VERSION ""

NS_ :

BS_:

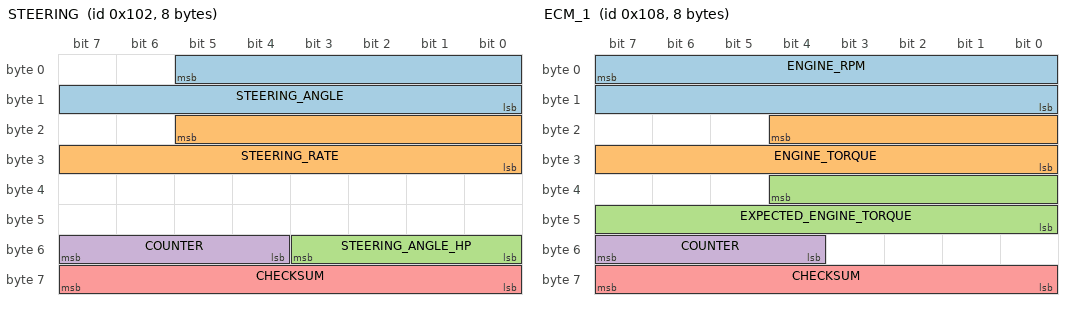
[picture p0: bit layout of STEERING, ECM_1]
BO_ 258 STEERING: 8 XXX
 SG_ STEERING_ANGLE : 5|14@0+ (0.5,-2048) [-2048|2047] "deg" XXX
 SG_ STEERING_RATE : 21|14@0+ (0.5,-2048) [-2048|2047] "deg/s" XXX
 SG_ STEERING_ANGLE_HP : 48|4@1+ (0.1,-0.4) [-0.4|0.4] "deg" XXX
 SG_ COUNTER : 55|4@0+ (1,0) [0|15] "" XXX
 SG_ CHECKSUM : 63|8@0+ (1,0) [0|255] "" XXX

BO_ 264 ECM_1: 8 XXX
 SG_ ENGINE_RPM : 7|16@0+ (1,0) [0|65535] "" XXX
 SG_ ENGINE_TORQUE : 20|13@0+ (0.25,-500) [-500|1547.5] "Nm" XXX
 SG_ EXPECTED_ENGINE_TORQUE : 36|13@0+ (0.25,-500) [-500|1547.5] "Nm" XXX
 SG_ COUNTER : 55|4@0+ (1,0) [0|15] "" XXX
 SG_ CHECKSUM : 63|8@0+ (1,0) [0|255] "" XXX

BO_ 280 ECM_TRQ: 8 XXX
 SG_ ENGINE_TORQ_MAX : 4|13@0+ (.25,-500) [-500|1547.5] "NM" XXX
 SG_ ENGINE_TORQ_MIN : 20|13@0+ (.25,-500) [-500|1547.5] "NM" XXX

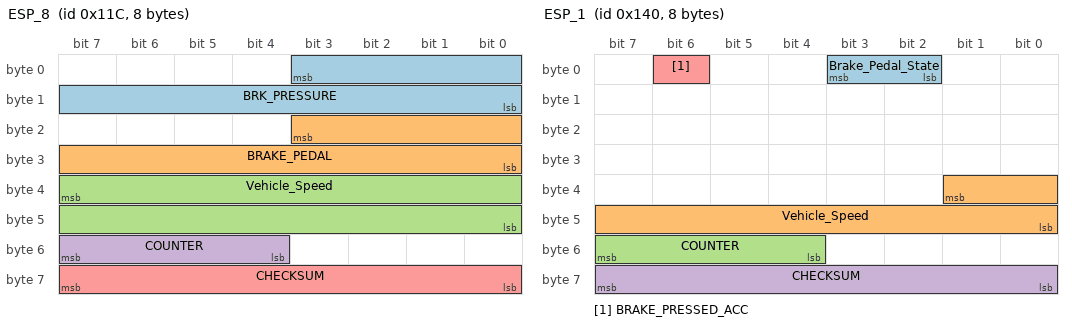
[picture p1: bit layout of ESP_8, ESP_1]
BO_ 284 ESP_8: 8 XXX
 SG_ BRK_PRESSURE : 3|12@0+ (1,0) [0|1] "" XXX
 SG_ BRAKE_PEDAL : 19|12@0+ (1,0) [0|1] "" XXX
 SG_ Vehicle_Speed : 39|16@0+ (0.0078125,0) [0|511.984375] "km/h" XXX
 SG_ COUNTER : 55|4@0+ (1,0) [0|15] "" XXX
 SG_ CHECKSUM : 63|8@0+ (1,0) [0|255] "" XXX

BO_ 320 ESP_1: 8 XXX
 SG_ Brake_Pedal_State : 2|2@1+ (1,0) [0|0] "" XXX
 SG_ Vehicle_Speed : 33|10@0+ (0.5,0) [0|511] "km/h" XXX
 SG_ COUNTER : 55|4@0+ (1,0) [0|15] "" XXX
 SG_ CHECKSUM : 63|8@0+ (1,0) [0|255] "" XXX
 SG_ BRAKE_PRESSED_ACC : 6|1@0+ (1,0) [0|3] "" XXX

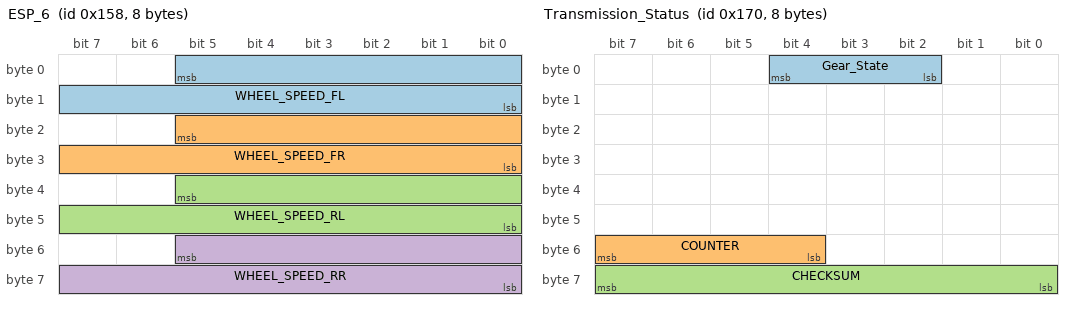
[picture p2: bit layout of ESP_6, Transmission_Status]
BO_ 344 ESP_6: 8 XXX
 SG_ WHEEL_SPEED_FL : 5|14@0+ (0.5,0) [0|8191] "rpm" XXX
 SG_ WHEEL_SPEED_FR : 21|14@0+ (0.5,0) [0|8191] "rpm" XXX
 SG_ WHEEL_SPEED_RL : 37|14@0+ (0.5,0) [0|8191] "rpm" XXX
 SG_ WHEEL_SPEED_RR : 53|14@0+ (0.5,0) [0|8191] "rpm" XXX

BO_ 368 Transmission_Status: 8 XXX
 SG_ Gear_State : 2|3@1+ (1,0) [0|15] "" XXX
 SG_ COUNTER : 55|4@0+ (1,0) [0|15] "" XXX
 SG_ CHECKSUM : 63|8@0+ (1,0) [0|255] "" XXX

BO_ 464 ORC_1: 8 XXX
 SG_ SEATBELT_DRIVER_UNLATCHED : 13|1@0+ (1,0) [0|1] "" XXX

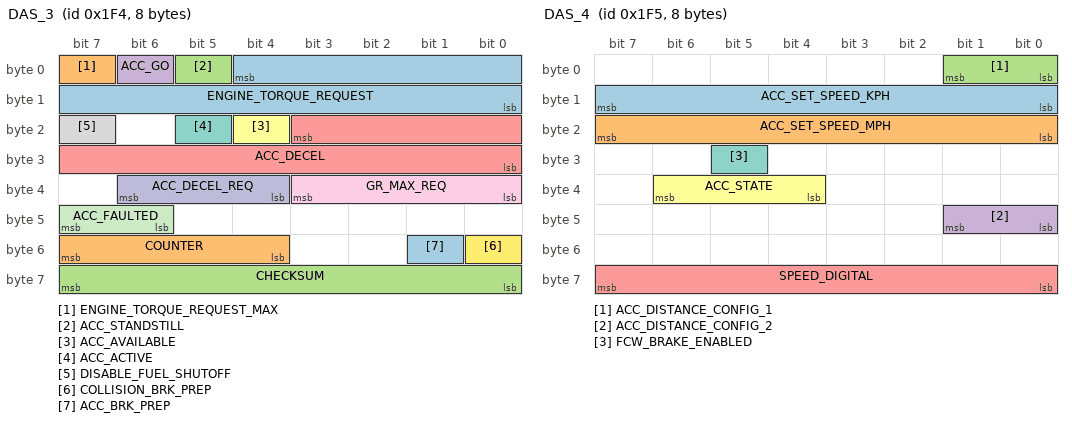
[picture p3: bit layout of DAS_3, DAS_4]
BO_ 500 DAS_3: 8 XXX
 SG_ ENGINE_TORQUE_REQUEST : 4|13@0+ (0.25,-500) [-500|1547.5] "Nm" XXX
 SG_ ENGINE_TORQUE_REQUEST_MAX : 7|1@0+ (1,0) [0|1] "" XXX
 SG_ ACC_STANDSTILL : 5|1@0+ (1,0) [0|1] ""  XXX
 SG_ ACC_GO : 6|1@1+ (1,0) [0|0] "" XXX
 SG_ ACC_DECEL : 19|12@0+ (0.004885,-16) [-16|4] "m/s2" XXX
 SG_ ACC_AVAILABLE : 20|1@0+ (1,0) [0|1] "" XXX
 SG_ ACC_ACTIVE : 21|1@0+ (1,0) [0|1] "" XXX
 SG_ DISABLE_FUEL_SHUTOFF : 23|1@1+ (1,0) [0|0] "" XXX
 SG_ GR_MAX_REQ : 32|4@1+ (1,0) [0|0] "" XXX
 SG_ ACC_DECEL_REQ : 36|3@1+ (1,0) [0|0] "" XXX
 SG_ ACC_FAULTED : 46|2@1+ (1,0) [0|0] "" XXX
 SG_ COLLISION_BRK_PREP : 48|1@1+ (1,0) [0|0] "" XXX
 SG_ ACC_BRK_PREP : 49|1@1+ (1,0) [0|0] "" XXX
 SG_ COUNTER : 55|4@0+ (1,0) [0|15] "" XXX
 SG_ CHECKSUM : 63|8@0+ (1,0) [0|255] "" XXX

BO_ 501 DAS_4: 8 XXX
 SG_ ACC_SET_SPEED_KPH : 15|8@0+ (1,0) [0|3] "km/h" XXX
 SG_ ACC_SET_SPEED_MPH : 23|8@0+ (1,0) [0|3] "mph" XXX
 SG_ ACC_DISTANCE_CONFIG_1 : 1|2@0+ (1,0) [0|3] "" XXX
 SG_ ACC_DISTANCE_CONFIG_2 : 41|2@0+ (1,0) [0|3] "" XXX
 SG_ SPEED_DIGITAL : 63|8@0+ (1,0) [0|255] "mph" XXX
 SG_ ACC_STATE : 38|3@0+ (1,0) [0|7] "" XXX
 SG_ FCW_BRAKE_ENABLED : 29|1@0+ (1,0) [0|1] "" XXX

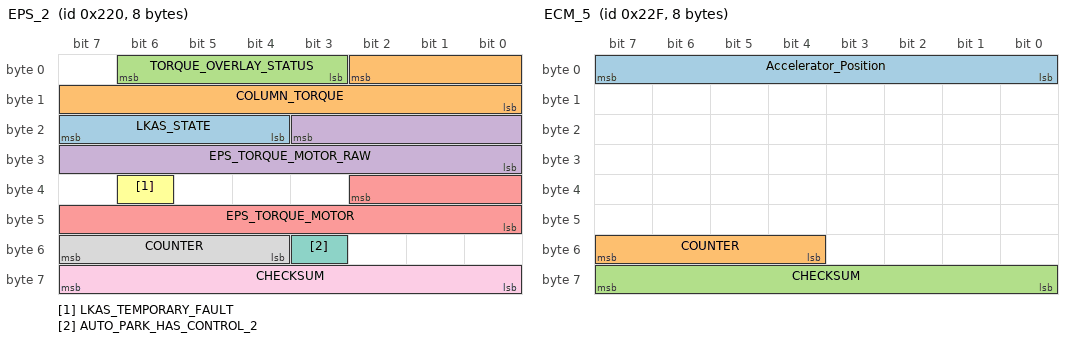
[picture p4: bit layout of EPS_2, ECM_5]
BO_ 544 EPS_2: 8 XXX
 SG_ LKAS_STATE : 23|4@0+ (1,0) [0|15] "" XXX
 SG_ COLUMN_TORQUE : 2|11@0+ (1,-1024) [-1024|1023] "" XXX
 SG_ TORQUE_OVERLAY_STATUS : 6|4@0+ (1,0) [0|15] "" XXX
 SG_ EPS_TORQUE_MOTOR_RAW : 19|12@0+ (1,-2048) [-2048|2047] "" XXX
 SG_ EPS_TORQUE_MOTOR : 34|11@0+ (1,-1024) [-1024|1023] "" XXX
 SG_ LKAS_TEMPORARY_FAULT : 38|1@0+ (1,0) [0|1] "" XXX
 SG_ AUTO_PARK_HAS_CONTROL_2 : 51|1@0+ (1,0) [0|1] "" XXX
 SG_ COUNTER : 55|4@0+ (1,0) [0|15] "" XXX
 SG_ CHECKSUM : 63|8@0+ (1,0) [0|255] "" XXX

BO_ 559 ECM_5: 8 XXX
 SG_ Accelerator_Position : 0|8@1+ (0.4,0) [0|100] "%" XXX
 SG_ COUNTER : 55|4@0+ (1,0) [0|15] "" XXX
 SG_ CHECKSUM : 63|8@0+ (1,0) [0|255] "" XXX

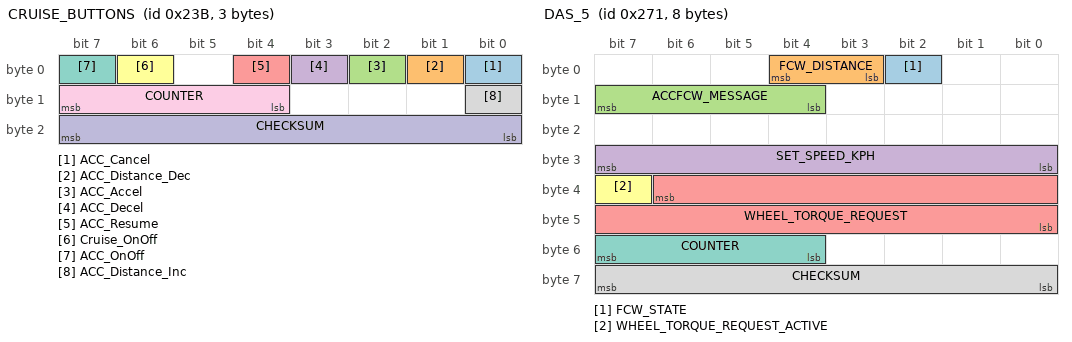
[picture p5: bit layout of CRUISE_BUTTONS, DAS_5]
BO_ 571 CRUISE_BUTTONS: 3 XXX
 SG_ ACC_Cancel : 0|1@1+ (1,0) [0|0] "" XXX
 SG_ ACC_Distance_Dec : 1|1@1+ (1,0) [0|0] "" XXX
 SG_ ACC_Accel : 2|1@1+ (1,0) [0|0] "" XXX
 SG_ ACC_Decel : 3|1@1+ (1,0) [0|0] "" XXX
 SG_ ACC_Resume : 4|1@0+ (1,0) [0|1] "" XXX
 SG_ Cruise_OnOff : 6|1@1+ (1,0) [0|0] "" XXX
 SG_ ACC_OnOff : 7|1@1+ (1,0) [0|0] "" XXX
 SG_ ACC_Distance_Inc : 8|1@1+ (1,0) [0|0] "" XXX
 SG_ COUNTER : 15|4@0+ (1,0) [0|15] "" XXX
 SG_ CHECKSUM : 23|8@0+ (1,0) [0|255] "" XXX

BO_ 625 DAS_5: 8 XXX
 SG_ FCW_STATE : 2|1@1+ (1,0) [0|0] ""  XXX
 SG_ FCW_DISTANCE : 3|2@1+ (1,0) [0|0] ""  XXX
 SG_ ACCFCW_MESSAGE : 12|4@1+ (1,0) [0|0] ""  XXX
 SG_ SET_SPEED_KPH : 24|8@1+ (1,0) [0|250] "km/h"  XXX
 SG_ WHEEL_TORQUE_REQUEST : 38|15@0+ (1,-7767) [-7767|24999] "Nm"  XXX
 SG_ WHEEL_TORQUE_REQUEST_ACTIVE : 39|1@1+ (1,0) [0|0] ""  XXX
 SG_ COUNTER : 55|4@0+ (1,0) [0|15] "" XXX
 SG_ CHECKSUM : 63|8@0+ (1,0) [0|255] "" XXX

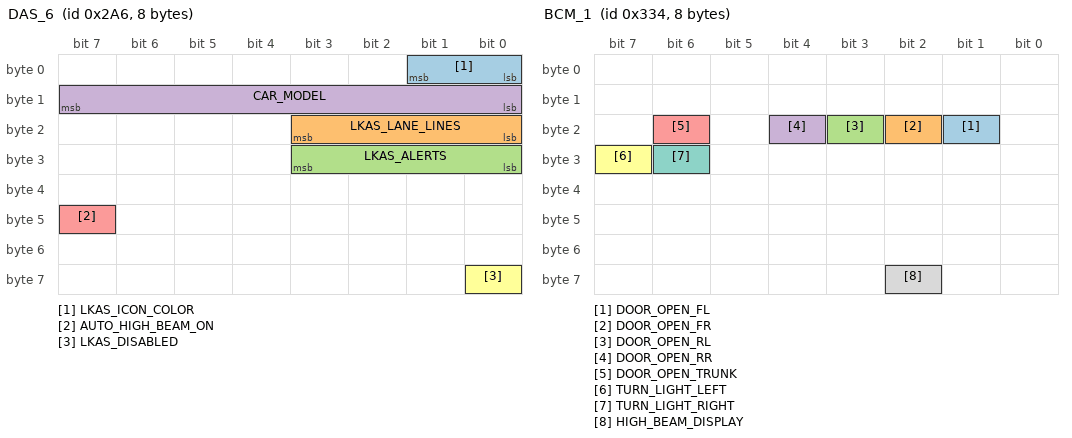
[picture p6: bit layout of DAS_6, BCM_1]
BO_ 678 DAS_6: 8 XXX
 SG_ LKAS_ICON_COLOR : 1|2@0+ (1,0) [0|3] "" XXX
 SG_ LKAS_LANE_LINES : 19|4@0+ (1,0) [0|1] "" XXX
 SG_ LKAS_ALERTS : 27|4@0+ (1,0) [0|1] "" XXX
 SG_ CAR_MODEL : 15|8@0+ (1,0) [0|255] "" XXX
 SG_ AUTO_HIGH_BEAM_ON : 47|1@1+ (1,0) [0|0] "" XXX
 SG_ LKAS_DISABLED : 56|1@1+ (1,0) [0|0] "" XXX

BO_ 720 BSM_1: 6 XXX
 SG_ RIGHT_STATUS : 5|1@0+ (1,0) [0|1] "" XXX
 SG_ LEFT_STATUS : 2|1@0+ (1,0) [0|1] "" XXX

BO_ 792 STEERING_LEVERS: 8 XXX
 SG_ TURN_SIGNALS : 0|2@1+ (1,0) [0|3] "" XXX
 SG_ HIGH_BEAM_PRESSED : 2|1@0+ (1,0) [0|3] "" XXX

BO_ 820 BCM_1: 8 XXX
 SG_ DOOR_OPEN_FL : 17|1@0+ (1,0) [0|1] "" XXX
 SG_ DOOR_OPEN_FR : 18|1@0+ (1,0) [0|1] "" XXX
 SG_ DOOR_OPEN_RL : 19|1@0+ (1,0) [0|1] "" XXX
 SG_ DOOR_OPEN_RR : 20|1@0+ (1,0) [0|1] "" XXX
 SG_ DOOR_OPEN_TRUNK : 22|1@0+ (1,0) [0|1] "" XXX
 SG_ TURN_LIGHT_LEFT : 31|1@0+ (1,0) [0|1] "" XXX
 SG_ TURN_LIGHT_RIGHT : 30|1@0+ (1,0) [0|1] "" XXX
 SG_ HIGH_BEAM_DISPLAY : 58|1@0+ (1,0) [0|1] "" XXX

BO_ 514 SPEED_1: 8 XXX
 SG_ SPEED_LEFT : 7|12@0+ (0.071028,0) [0|65535] "m/s" XXX
 SG_ SPEED_RIGHT : 23|12@0+ (0.071028,0) [0|1023] "m/s" XXX

BO_ 653 BRAKE_MODULE: 2 XXX
 SG_ BRAKE_PRESSURE : 15|8@0+ (1,0) [0|255] "" XXX
 SG_ BRAKE_PRESSED : 4|1@0+ (1,0) [0|4] "" XXX

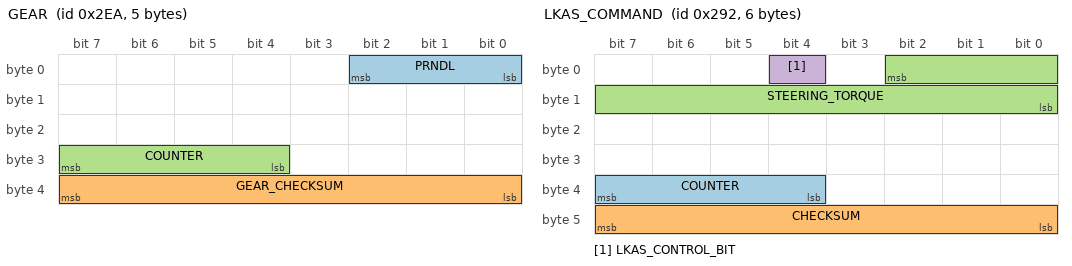
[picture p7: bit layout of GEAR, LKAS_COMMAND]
BO_ 746 GEAR: 5 XXX
 SG_ PRNDL : 2|3@0+ (1,0) [0|7] "" XXX
 SG_ GEAR_CHECKSUM : 39|8@0+ (1,0) [0|255] "" XXX
 SG_ COUNTER : 31|4@0+ (1,0) [0|15] "" XXX

BO_ 736 TRIP: 8 XXX
 SG_ COUNTER : 7|16@0+ (1,0) [0|65535] "Meters" XXX
 SG_ COUNTER_2 : 23|16@0+ (1,0) [0|65535] "Meters" XXX

BO_ 658 LKAS_COMMAND: 6 XXX
 SG_ COUNTER : 39|4@0+ (1,0) [0|15] "" XXX
 SG_ CHECKSUM : 47|8@0+ (1,0) [0|255] "" XXX
 SG_ STEERING_TORQUE : 2|11@0+ (1,-1024) [0|1] "" XXX
 SG_ LKAS_CONTROL_BIT : 4|1@0+ (1,0) [0|1] "" XXX

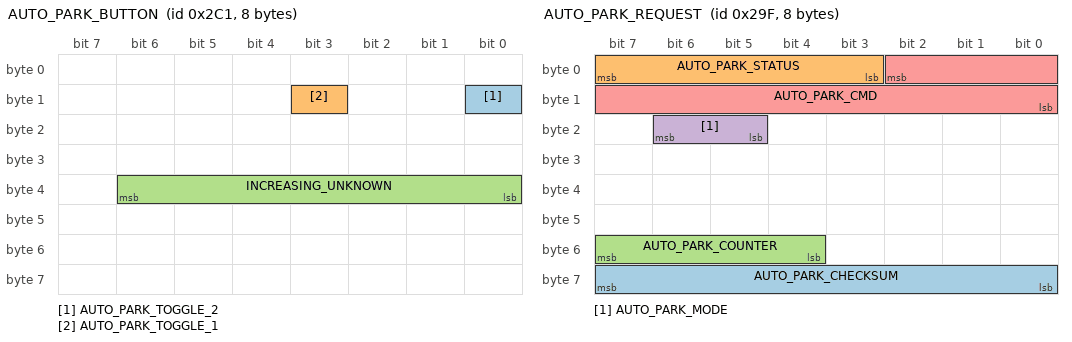
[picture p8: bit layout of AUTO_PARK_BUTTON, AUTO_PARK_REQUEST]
BO_ 705 AUTO_PARK_BUTTON: 8 XXX
 SG_ AUTO_PARK_TOGGLE_2 : 8|1@0+ (1,0) [0|1] "" XXX
 SG_ AUTO_PARK_TOGGLE_1 : 11|1@0+ (1,0) [0|1] "" XXX
 SG_ INCREASING_UNKNOWN : 38|7@0+ (1,0) [0|15] "" XXX

BO_ 719 AUTO_PARK_SIGNALS_1: 8 XXX
 SG_ AUTO_PARK_UNKNOWN_1 : 7|16@0+ (1,0) [0|31] "" XXX

BO_ 671 AUTO_PARK_REQUEST: 8 XXX
 SG_ AUTO_PARK_CHECKSUM : 63|8@0+ (1,0) [0|255] "" XXX
 SG_ AUTO_PARK_STATUS : 7|5@0+ (1,0) [0|15] "" XXX
 SG_ AUTO_PARK_COUNTER : 55|4@0+ (1,0) [0|15] "" XXX
 SG_ AUTO_PARK_MODE : 22|2@0+ (1,0) [0|3] "" XXX
 SG_ AUTO_PARK_CMD : 2|11@0+ (1,-1024) [0|1] "NM" XXX

BO_ 784 AUTO_PARK_LESS_INTERESTING: 8 XXX
 SG_ INCREASING_UNKNOWN : 55|8@0+ (1,0) [0|7] "" XXX
 SG_ AUTO_PARK_PERPENDICULAR_2 : 61|1@0+ (1,0) [0|255] "" XXX

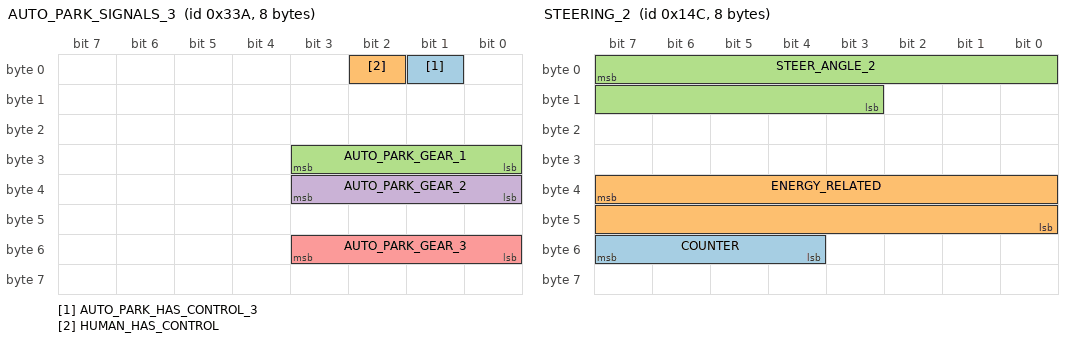
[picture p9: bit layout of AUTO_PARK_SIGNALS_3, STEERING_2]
BO_ 826 AUTO_PARK_SIGNALS_3: 8 XXX
 SG_ AUTO_PARK_HAS_CONTROL_3 : 1|1@0+ (1,0) [0|1] "" XXX
 SG_ HUMAN_HAS_CONTROL : 2|1@0+ (1,0) [0|1] "" XXX
 SG_ AUTO_PARK_GEAR_1 : 27|4@0+ (1,0) [0|255] "" XXX
 SG_ AUTO_PARK_GEAR_2 : 35|4@0+ (1,0) [0|15] "" XXX
 SG_ AUTO_PARK_GEAR_3 : 51|4@0+ (1,0) [0|15] "" XXX

BO_ 332 STEERING_2: 8 XXX
 SG_ COUNTER : 55|4@0+ (1,0) [0|15] "" XXX
 SG_ ENERGY_RELATED : 39|16@0+ (1,0) [0|65535] "" XXX
 SG_ STEER_ANGLE_2 : 7|13@0+ (0.3187251,-1307.888) [-360|360] "deg" XXX

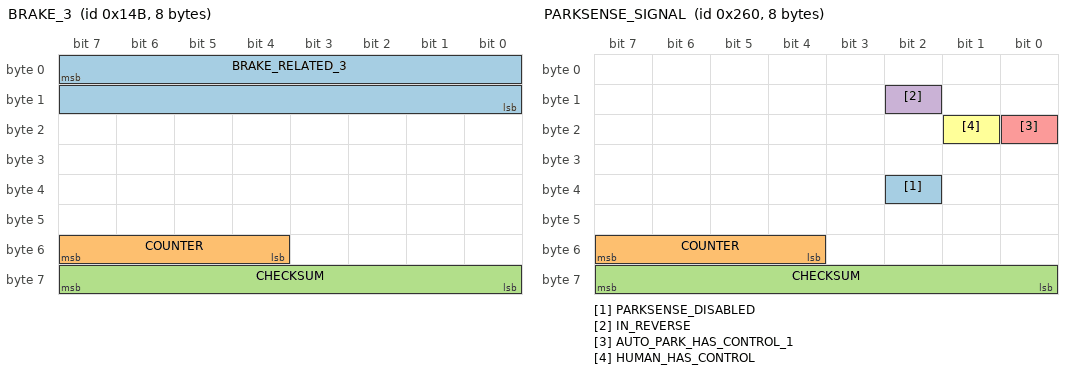
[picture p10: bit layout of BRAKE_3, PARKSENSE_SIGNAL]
BO_ 331 BRAKE_3: 8 XXX
 SG_ BRAKE_RELATED_3 : 7|16@0+ (1,0) [0|65535] "" XXX
 SG_ COUNTER : 55|4@0+ (1,0) [0|15] "" XXX
 SG_ CHECKSUM : 63|8@0+ (1,0) [0|255] "" XXX

BO_ 608 PARKSENSE_SIGNAL: 8 XXX
 SG_ PARKSENSE_DISABLED : 34|1@0+ (1,0) [0|1] "" XXX
 SG_ COUNTER : 55|4@0+ (1,0) [0|15] "" XXX
 SG_ CHECKSUM : 63|8@0+ (1,0) [0|255] "" XXX
 SG_ IN_REVERSE : 10|1@0+ (1,0) [0|255] "" XXX
 SG_ AUTO_PARK_HAS_CONTROL_1 : 16|1@0+ (1,0) [0|255] "" XXX
 SG_ HUMAN_HAS_CONTROL : 17|1@0+ (1,0) [0|3] "" XXX

BO_ 729 LKAS_HEARTBIT: 5 XXX
 SG_ LKAS_STATUS_OK : 31|16@0+ (1,0) [0|65535] "" XXX

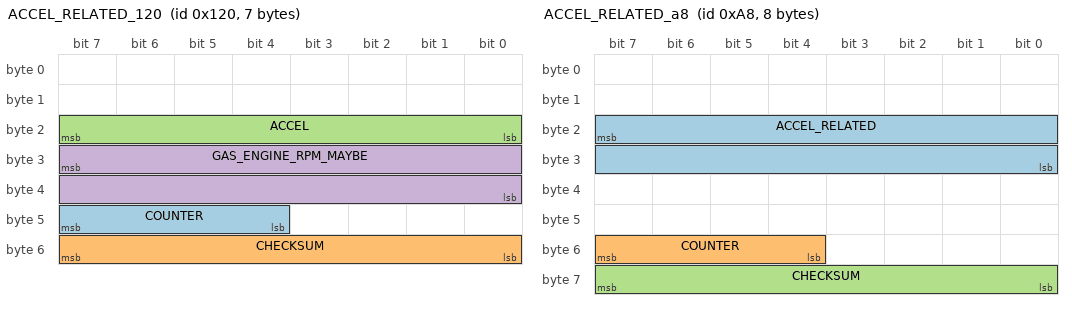
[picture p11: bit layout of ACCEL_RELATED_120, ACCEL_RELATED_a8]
BO_ 288 ACCEL_RELATED_120: 7 XXX
 SG_ COUNTER : 47|4@0+ (1,0) [0|15] "" XXX
 SG_ CHECKSUM : 55|8@0+ (1,0) [0|255] "" XXX
 SG_ ACCEL : 23|8@0+ (1,0) [0|255] "" XXX
 SG_ GAS_ENGINE_RPM_MAYBE : 31|16@0+ (1,0) [0|65535] "" XXX

BO_ 257 ACCEL_RELATED_101: 5 XXX
 SG_ ENERGY_OR_RPM : 31|8@0+ (1,0) [0|255] "" XXX

BO_ 825 AUDIBLE_BEEP_339: 2 XXX
 SG_ BEEP_339 : 7|16@0+ (1,0) [0|65535] "" XXX

BO_ 168 ACCEL_RELATED_a8: 8 XXX
 SG_ ACCEL_RELATED : 23|16@0+ (1,0) [0|65535] "" XXX
 SG_ COUNTER : 55|4@0+ (1,0) [0|15] "" XXX
 SG_ CHECKSUM : 63|8@0+ (1,0) [0|255] "" XXX

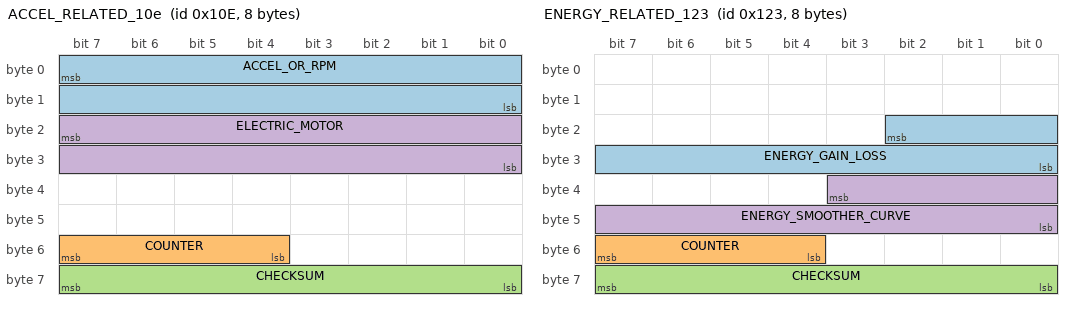
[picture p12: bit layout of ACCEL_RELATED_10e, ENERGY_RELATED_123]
BO_ 270 ACCEL_RELATED_10e: 8 XXX
 SG_ ACCEL_OR_RPM : 7|16@0+ (1,0) [0|255] "" XXX
 SG_ COUNTER : 55|4@0+ (1,0) [0|15] "" XXX
 SG_ CHECKSUM : 63|8@0+ (1,0) [0|255] "" XXX
 SG_ ELECTRIC_MOTOR : 23|16@0+ (1,0) [0|65535] "" XXX

BO_ 291 ENERGY_RELATED_123: 8 XXX
 SG_ ENERGY_GAIN_LOSS : 18|11@0- (1,0) [0|255] "" XXX
 SG_ COUNTER : 55|4@0+ (1,0) [0|15] "" XXX
 SG_ CHECKSUM : 63|8@0+ (1,0) [0|255] "" XXX
 SG_ ENERGY_SMOOTHER_CURVE : 35|12@0+ (1,0) [0|2047] "" XXX

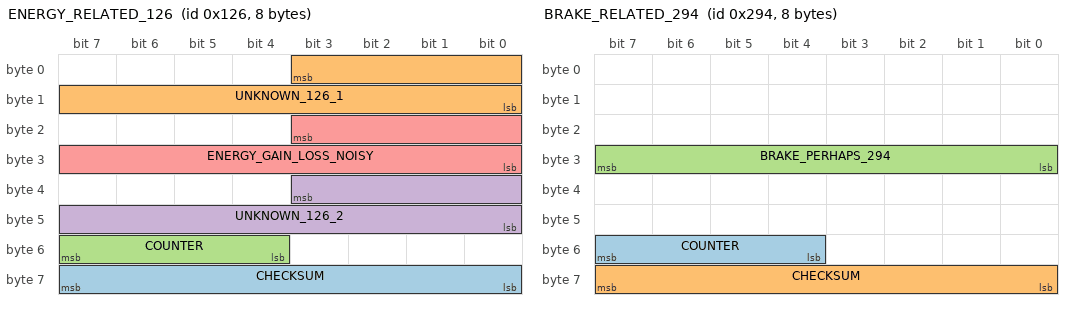
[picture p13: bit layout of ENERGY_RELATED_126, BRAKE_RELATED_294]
BO_ 294 ENERGY_RELATED_126: 8 XXX
 SG_ CHECKSUM : 63|8@0+ (1,0) [0|255] "" XXX
 SG_ UNKNOWN_126_1 : 3|12@0+ (1,0) [0|4095] "" XXX
 SG_ COUNTER : 55|4@0+ (1,0) [0|15] "" XXX
 SG_ UNKNOWN_126_2 : 35|12@0+ (1,0) [0|4095] "" XXX
 SG_ ENERGY_GAIN_LOSS_NOISY : 19|12@0+ (1,0) [0|2047] "" XXX

BO_ 308 ACCEL_GAS_134: 8 XXX
 SG_ COUNTER : 55|4@0+ (1,0) [0|15] "" XXX
 SG_ ACCEL_134 : 46|7@0+ (1,0) [0|127] "" XXX

BO_ 532 ENERGY_RELATED_214: 8 XXX
 SG_ NOISY_SLOWLY_DECREASING : 16|9@0+ (1,0) [0|255] "" XXX
 SG_ ENERGY_RELATED : 0|9@0+ (1,0) [0|255] "" XXX

BO_ 655 CHARGING_MAYBE_28F: 8 XXX
 SG_ CHARGING : 1|2@0+ (1,0) [0|3] "" XXX

BO_ 660 BRAKE_RELATED_294: 8 XXX
 SG_ COUNTER : 55|4@0+ (1,0) [0|15] "" XXX
 SG_ CHECKSUM : 63|8@0+ (1,0) [0|255] "" XXX
 SG_ BRAKE_PERHAPS_294 : 31|8@0+ (1,0) [0|255] "" XXX

BO_ 764 ACCEL_RELATED_2FC: 8 XXX
 SG_ ACCEL_2FC : 13|6@0+ (1,0) [0|255] "" XXX

BO_ 816 TRACTION_BUTTON: 8 XXX
 SG_ TRACTION_OFF : 19|1@0+ (1,0) [0|3] "" XXX
 SG_ TOGGLE_PARKSENSE : 52|1@0+ (1,0) [0|3] "" XXX

BO_ 878 ACCEL_RELATED_36E: 8 XXX
 SG_ ACCEL_OR_RPM_2 : 15|8@0+ (1,0) [0|255] "" XXX
 SG_ ACCEL_OR_RPM_1 : 7|8@0+ (1,0) [0|255] "" XXX

BO_ 324 SPEED_2: 8 XXX
 SG_ SPEED_2 : 31|16@0+ (0.01,0) [0|255] "m/s" XXX

BO_ 832 UNKNOWN_340: 8 XXX
 SG_ SPEED_DIGITAL : 63|8@0+ (1,0) [0|255] "mph" XXX

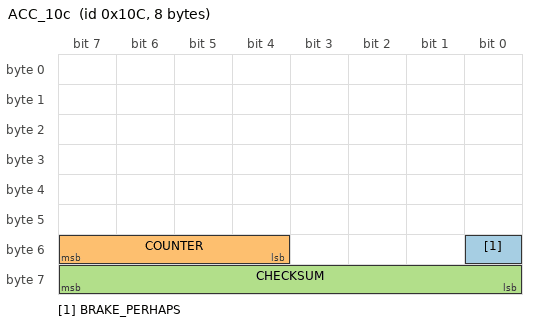
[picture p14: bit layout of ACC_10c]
BO_ 268 ACC_10c: 8 XXX
 SG_ BRAKE_PERHAPS : 48|1@0+ (1,0) [0|3] "" XXX
 SG_ COUNTER : 55|4@0+ (1,0) [0|15] "" XXX
 SG_ CHECKSUM : 63|8@0+ (1,0) [0|255] "" XXX

CM_ "AUTOGENERATED FILE, DO NOT EDIT";

CM_ "Imported file _honda_common.dbc starts here";
CM_ SG_ 304 "Seems to be platform-agnostic";
CM_ SG_ 316 "Should exist on Nidec";
CM_ SG_ 420 BRAKE_HOLD_RELATED "On when Brake Hold engaged";
CM_ SG_ 490 LONG_ACCEL "wheel speed derivative, noisy and zero snapping";
CM_ SG_ 773 PASS_AIRBAG_ON "Might just be indicator light";
CM_ SG_ 773 PASS_AIRBAG_OFF "Might just be indicator light";
CM_ SG_ 780 CRUISE_SPEED "255 = no speed";
CM_ SG_ 780 PCM_SPEED "Used by Nidec";
CM_ SG_ 780 PCM_GAS "Used by Nidec";
CM_ SG_ 804 CRUISE_SPEED_PCM "255 = no speed";

CM_ "Imported file _bosch_2018.dbc starts here";
CM_ SG_ 450 EPB_STATE "3: On, 2: Disengaging, 1: Engaging, 0: Off";
CM_ SG_ 576 LINE_DISTANCE_VISIBLE "Length of line visible, undecoded";
CM_ SG_ 577 LINE_FAR_EDGE_POSITION "Appears to be a measure of line thickness, indicates location of the portion of the line furthest from the car, undecoded";
CM_ SG_ 577 LINE_PARAMETER "Unclear if this is low quality line curvature rate or if this is something else, but it is correlated with line curvature, undecoded";
CM_ SG_ 577 LINE_DASHED "1 = line is dashed";
CM_ SG_ 577 LINE_SOLID "1 = line is solid";

CM_ "Imported file _bosch_adas_2018.dbc starts here";
CM_ SG_ 479 CONTROL_ON "Set to 5 when car is being controlled";
CM_ SG_ 479 AEB_STATUS "set for the duration of AEB event";
CM_ SG_ 479 AEB_BRAKING "set when braking is commanded during AEB event";
CM_ SG_ 479 AEB_PREPARE "set 1s before AEB";
CM_ SG_ 829 BEEP "beeps are pleasant, chimes are for warnngs etc...";

CM_ "Imported file _steering_sensors_a.dbc starts here";
CM_ "honda_accord_2018_can.dbc starts here";

VAL_ 481 DistanceButton 1 "Active" 0 "Inactive" ;
VAL_ 481 LKAButton 1 "Active" 0 "Inactive" ;
VAL_ 481 ACCButtons 6 "Cancel" 5 "Main" 3 "Set" 2 "Resume" 1 "None" ;
VAL_ 309 PRNDL 3 "Reverse" 2 "Drive" 1 "Neutral" 0 "Park" ;
VAL_ 338 LKASteeringCmdActive 1 "Active" 0 "Inactive" ;
VAL_ 338 LKASMode 2 "supercruise" 1 "lkas" 0 "Inactive" ;
VAL_ 880 ACCLeadCar 1 "Present" 0 "Not Present" ;
VAL_ 880 ACCGapLevel 3 "Far" 2 "Med" 1 "Near" 0 "Inactive" ;
VAL_ 880 ACCResumeButton 1 "Pressed" 0 "Depressed" ;
VAL_ 880 ACCCmdActive 1 "Active" 0 "Inactive" ;
VAL_ 356 LKATorqueDeliveredStatus 7 "Override Fault" 6 "LKAS Fault but Responsive" 5 "TBD but Responsive" 4 "TBD but Responsive" 3 "Fault" 1 "Active" 0 "Inactive" ;
VAL_ 489 BrakePedalPressed 1 "Pressed" 0 "Depressed" ;
VAL_ 715 GasRegenCmdActiveInv 1 "Inactive" 0 "Active" ;
